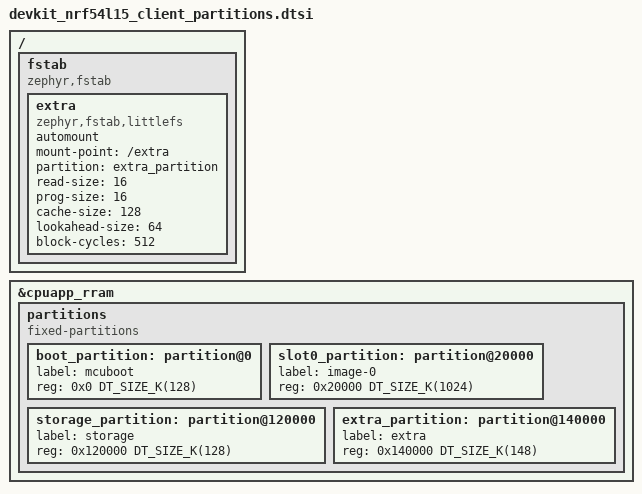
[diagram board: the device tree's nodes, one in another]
/* Copyright (c) 2026 FoBE Studio; SPDX-License-Identifier: Apache-2.0 */

/ {
	fstab: fstab {
		compatible = "zephyr,fstab";

		extra: extra {
			compatible = "zephyr,fstab,littlefs";
			automount;
			mount-point = "/extra";
			partition = <&extra_partition>;
			read-size = <16>;
			prog-size = <16>;
			cache-size = <128>;
			lookahead-size = <64>;
			block-cycles = <512>;
		};
	};
};

&cpuapp_rram {
	/delete-node/ partitions;

	partitions {
		compatible = "fixed-partitions";
		#address-cells = <1>;
		#size-cells = <1>;
		ranges;

		boot_partition: partition@0 {
			label = "mcuboot";
			reg = <0x0 DT_SIZE_K(128)>;
		};

		slot0_partition: partition@20000 {
			label = "image-0";
			reg = <0x20000 DT_SIZE_K(1024)>;
		};

		storage_partition: partition@120000 {
			label = "storage";
			reg = <0x120000 DT_SIZE_K(128)>;
		};

		extra_partition: partition@140000 {
			label = "extra";
			reg = <0x140000 DT_SIZE_K(148)>;
		};
	};
};
